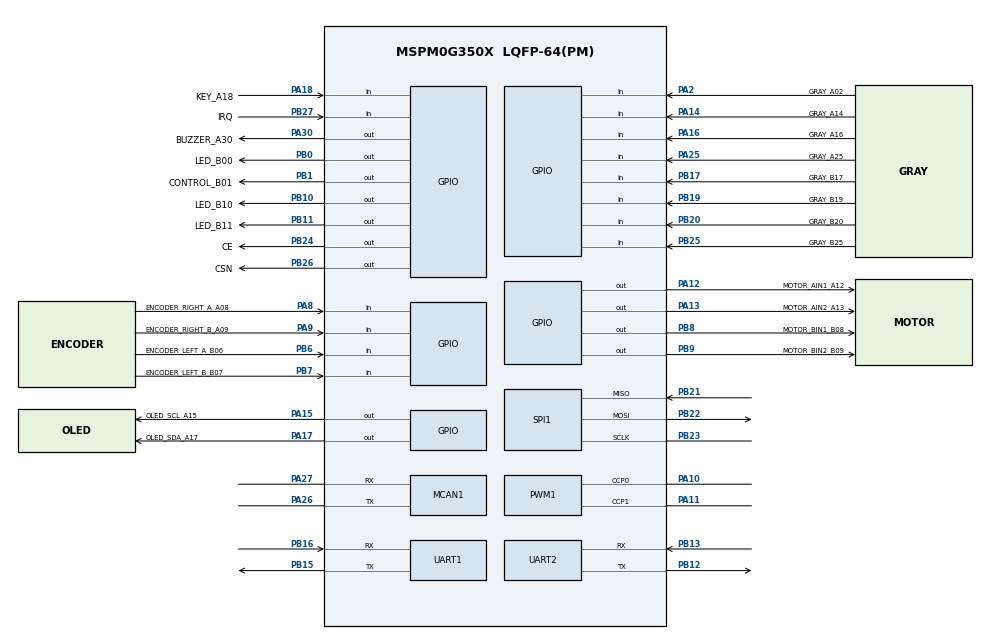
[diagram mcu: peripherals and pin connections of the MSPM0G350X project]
/**
 *
 * @cliArgs --device "MSPM0G350X" --part "Default" --package "LQFP-64(PM)" --product "mspm0_sdk@2.11.00.07"
 * @versions {"tool":"1.28.0+4696"}
 */

/**
 * Import the modules used in this configuration.
 */
const GPIO   = scripting.addModule("/ti/driverlib/GPIO", {}, false);
const GPIO1  = GPIO.addInstance();
const GPIO2  = GPIO.addInstance();
const GPIO3  = GPIO.addInstance();
const GPIO4  = GPIO.addInstance();
const GPIO5  = GPIO.addInstance();
const GPIO6  = GPIO.addInstance();
const GPIO7  = GPIO.addInstance();
const GPIO8  = GPIO.addInstance();
const GPIO9  = GPIO.addInstance();
const MCAN   = scripting.addModule("/ti/driverlib/MCAN", {}, false);
const MCAN1  = MCAN.addInstance();
const PWM    = scripting.addModule("/ti/driverlib/PWM", {}, false);
const PWM1   = PWM.addInstance();
const SPI    = scripting.addModule("/ti/driverlib/SPI", {}, false);
const SPI1   = SPI.addInstance();
const SYSCTL = scripting.addModule("/ti/driverlib/SYSCTL");
const UART   = scripting.addModule("/ti/driverlib/UART", {}, false);
const UART1  = UART.addInstance();
const UART2  = UART.addInstance();

/**
 * Write custom configuration values to the imported modules.
 */
GPIO1.$name                         = "GPIO_LEDS";
GPIO1.associatedPins.create(3);
GPIO1.associatedPins[0].$name       = "LED_B00";
GPIO1.associatedPins[0].pin.$assign = "PB0";
GPIO1.associatedPins[1].$name       = "LED_B10";
GPIO1.associatedPins[1].pin.$assign = "PB10";
GPIO1.associatedPins[2].$name       = "LED_B11";
GPIO1.associatedPins[2].pin.$assign = "PB11";

const Board = scripting.addModule("/ti/driverlib/Board", {}, false);

GPIO2.$name                         = "GPIO_GRAY";
GPIO2.associatedPins.create(8);
GPIO2.associatedPins[0].$name       = "GRAY_A02";
GPIO2.associatedPins[0].direction   = "INPUT";
GPIO2.associatedPins[0].pin.$assign = "PA2";
GPIO2.associatedPins[1].$name       = "GRAY_B19";
GPIO2.associatedPins[1].direction   = "INPUT";
GPIO2.associatedPins[1].pin.$assign = "PB19";
GPIO2.associatedPins[2].$name       = "GRAY_B17";
GPIO2.associatedPins[2].direction   = "INPUT";
GPIO2.associatedPins[2].pin.$assign = "PB17";
GPIO2.associatedPins[3].$name       = "GRAY_A16";
GPIO2.associatedPins[3].direction   = "INPUT";
GPIO2.associatedPins[3].pin.$assign = "PA16";
GPIO2.associatedPins[4].$name       = "GRAY_A14";
GPIO2.associatedPins[4].direction   = "INPUT";
GPIO2.associatedPins[4].pin.$assign = "PA14";
GPIO2.associatedPins[5].$name       = "GRAY_B20";
GPIO2.associatedPins[5].direction   = "INPUT";
GPIO2.associatedPins[5].pin.$assign = "PB20";
GPIO2.associatedPins[6].$name       = "GRAY_B25";
GPIO2.associatedPins[6].direction   = "INPUT";
GPIO2.associatedPins[6].pin.$assign = "PB25";
GPIO2.associatedPins[7].$name       = "GRAY_A25";
GPIO2.associatedPins[7].direction   = "INPUT";
GPIO2.associatedPins[7].pin.$assign = "PA25";

GPIO3.$name                                 = "GPIO_KEY";
GPIO3.associatedPins.create(2);
GPIO3.associatedPins[0].$name               = "KEY_A18";
GPIO3.associatedPins[0].direction           = "INPUT";
GPIO3.associatedPins[0].internalResistor    = "PULL_UP";
GPIO3.associatedPins[0].interruptEn         = true;
GPIO3.associatedPins[0].assignedPort        = "PORTA";
GPIO3.associatedPins[0].assignedPortSegment = "Upper";
GPIO3.associatedPins[0].assignedPin         = "18";
GPIO3.associatedPins[0].polarity            = "RISE_FALL";
GPIO3.associatedPins[0].pin.$assign         = "PA18";
GPIO3.associatedPins[1].$name               = "KEY_B14";
GPIO3.associatedPins[1].direction           = "INPUT";
GPIO3.associatedPins[1].internalResistor    = "PULL_UP";
GPIO3.associatedPins[1].assignedPin         = "14";
GPIO3.associatedPins[1].assignedPort        = "PORTB";
GPIO3.associatedPins[1].assignedPortSegment = "Lower";
GPIO3.associatedPins[1].interruptEn         = true;
GPIO3.associatedPins[1].polarity            = "RISE_FALL";

GPIO4.$name                              = "GPIO_OLED";
GPIO4.associatedPins.create(2);
GPIO4.associatedPins[0].$name            = "OLED_SCL_A15";
GPIO4.associatedPins[0].initialValue     = "SET";
GPIO4.associatedPins[0].internalResistor = "PULL_UP";
GPIO4.associatedPins[0].hiZ              = "ENABLE";
GPIO4.associatedPins[0].pin.$assign      = "PA15";
GPIO4.associatedPins[1].$name            = "OLED_SDA_A17";
GPIO4.associatedPins[1].initialValue     = "SET";
GPIO4.associatedPins[1].internalResistor = "PULL_UP";
GPIO4.associatedPins[1].hiZ              = "ENABLE";
GPIO4.associatedPins[1].pin.$assign      = "PA17";

GPIO5.$name                         = "GPIO_MOTOR_DIR";
GPIO5.associatedPins.create(4);
GPIO5.associatedPins[0].$name       = "MOTOR_AIN1_A12";
GPIO5.associatedPins[0].initialValue = "CLEARED";
GPIO5.associatedPins[0].pin.$assign = "PA12";
GPIO5.associatedPins[1].$name       = "MOTOR_AIN2_A13";
GPIO5.associatedPins[1].initialValue = "CLEARED";
GPIO5.associatedPins[1].pin.$assign = "PA13";
GPIO5.associatedPins[2].$name       = "MOTOR_BIN1_B08";
GPIO5.associatedPins[2].initialValue = "CLEARED";
GPIO5.associatedPins[2].pin.$assign = "PB8";
GPIO5.associatedPins[3].$name       = "MOTOR_BIN2_B09";
GPIO5.associatedPins[3].initialValue = "CLEARED";
GPIO5.associatedPins[3].pin.$assign = "PB9";

GPIO6.$name                                 = "GPIO_ENCODER";
GPIO6.associatedPins.create(4);
GPIO6.associatedPins[0].$name               = "ENCODER_LEFT_A_B06";
GPIO6.associatedPins[0].direction           = "INPUT";
GPIO6.associatedPins[0].internalResistor    = "PULL_UP";
GPIO6.associatedPins[0].interruptEn         = true;
GPIO6.associatedPins[0].assignedPort        = "PORTB";
GPIO6.associatedPins[0].assignedPortSegment = "Lower";
GPIO6.associatedPins[0].assignedPin         = "6";
GPIO6.associatedPins[0].polarity            = "RISE_FALL";
GPIO6.associatedPins[0].pin.$assign         = "PB6";
GPIO6.associatedPins[1].$name               = "ENCODER_LEFT_B_B07";
GPIO6.associatedPins[1].direction           = "INPUT";
GPIO6.associatedPins[1].internalResistor    = "PULL_UP";
GPIO6.associatedPins[1].interruptEn         = true;
GPIO6.associatedPins[1].assignedPort        = "PORTB";
GPIO6.associatedPins[1].assignedPortSegment = "Lower";
GPIO6.associatedPins[1].assignedPin         = "7";
GPIO6.associatedPins[1].polarity            = "RISE_FALL";
GPIO6.associatedPins[1].pin.$assign         = "PB7";
GPIO6.associatedPins[2].$name               = "ENCODER_RIGHT_A_A08";
GPIO6.associatedPins[2].direction           = "INPUT";
GPIO6.associatedPins[2].internalResistor    = "PULL_UP";
GPIO6.associatedPins[2].interruptEn         = true;
GPIO6.associatedPins[2].assignedPort        = "PORTA";
GPIO6.associatedPins[2].assignedPortSegment = "Lower";
GPIO6.associatedPins[2].assignedPin         = "8";
GPIO6.associatedPins[2].polarity            = "RISE_FALL";
GPIO6.associatedPins[2].pin.$assign         = "PA8";
GPIO6.associatedPins[3].$name               = "ENCODER_RIGHT_B_A09";
GPIO6.associatedPins[3].direction           = "INPUT";
GPIO6.associatedPins[3].internalResistor    = "PULL_UP";
GPIO6.associatedPins[3].interruptEn         = true;
GPIO6.associatedPins[3].assignedPort        = "PORTA";
GPIO6.associatedPins[3].assignedPortSegment = "Lower";
GPIO6.associatedPins[3].assignedPin         = "9";
GPIO6.associatedPins[3].polarity            = "RISE_FALL";
GPIO6.associatedPins[3].pin.$assign         = "PA9";

GPIO7.$name                              = "GPIO_BUZZER";
GPIO7.associatedPins[0].$name            = "BUZZER_A30";
GPIO7.associatedPins[0].initialValue     = "CLEARED";
GPIO7.associatedPins[0].pin.$assign      = "PA30";

GPIO8.$name                          = "GPIO_NRF24";
GPIO8.associatedPins.create(3);
GPIO8.associatedPins[0].$name        = "CE";
GPIO8.associatedPins[0].initialValue = "CLEARED";
GPIO8.associatedPins[0].pin.$assign  = "PB24";
GPIO8.associatedPins[1].$name        = "CSN";
GPIO8.associatedPins[1].initialValue = "SET";
GPIO8.associatedPins[1].pin.$assign  = "PB26";
GPIO8.associatedPins[2].$name        = "IRQ";
GPIO8.associatedPins[2].direction    = "INPUT";
GPIO8.associatedPins[2].internalResistor = "PULL_UP";
GPIO8.associatedPins[2].pin.$assign  = "PB27";

GPIO9.$name                          = "GPIO_ELECTROMAGNET";
GPIO9.associatedPins[0].$name        = "CONTROL_B01";
GPIO9.associatedPins[0].initialValue = "CLEARED";
GPIO9.associatedPins[0].pin.$assign  = "PB1";

SPI1.$name                      = "SPI_NRF24";
SPI1.targetBitRate              = 1000000;
SPI1.chipSelect                 = [];
SPI1.frameFormat                = "MOTO3";
SPI1.peripheral.$assign         = "SPI1";
SPI1.peripheral.sclkPin.$assign = "PB23";
SPI1.peripheral.mosiPin.$assign = "PB22";
SPI1.peripheral.misoPin.$assign = "PB21";

MCAN1.$name                    = "MCAN_GIMBAL";
MCAN1.additionalCoreConfig     = true;
MCAN1.rrfe                     = true;
MCAN1.rrfs                     = true;
MCAN1.anfe                     = "2";
MCAN1.anfs                     = "2";
MCAN1.lss                      = 0;
MCAN1.flesa                    = 0;
MCAN1.lse                      = 1;
MCAN1.extFiltElem              = "001";
MCAN1.extFiltType              = "00";
MCAN1.extFiltID1               = 0x100;
MCAN1.extFiltID2               = 0xFFFF;
MCAN1.txStartAddr              = 8;
MCAN1.txBufNum                 = 1;
MCAN1.txFIFOSize               = 0;
MCAN1.txBufElemSize            = "DL_MCAN_ELEM_SIZE_8BYTES";
MCAN1.txEventFIFOStartAddr     = 24;
MCAN1.txEventFIFOSize          = 0;
MCAN1.txEventFIFOWaterMark     = 0;
MCAN1.rxFIFO0startAddr         = 24;
MCAN1.rxFIFO0size              = 8;
MCAN1.rxFIFO0waterMark         = 1;
MCAN1.rxFIFO1startAddr         = 152;
MCAN1.rxFIFO1size              = 0;
MCAN1.rxFIFO1waterMark         = 0;
MCAN1.rxBufStartAddr           = 152;
MCAN1.rxFIFO0ElemSize          = "DL_MCAN_ELEM_SIZE_8BYTES";
MCAN1.rxFIFO1ElemSize          = "DL_MCAN_ELEM_SIZE_8BYTES";
MCAN1.rxBufElemSize            = "DL_MCAN_ELEM_SIZE_8BYTES";
MCAN1.desiredNomRate           = 500;
MCAN1.enableInterrupt          = true;
MCAN1.interruptFlags           = ["DL_MCAN_INTERRUPT_RF0N"];
MCAN1.interruptLine            = ["DL_MCAN_INTR_LINE_NUM_1"];
MCAN1.interruptLine1Flag       = ["DL_MCAN_INTR_MASK_ALL"];
MCAN1.m0interrupts             = ["DL_MCAN_MSP_INTERRUPT_LINE1"];
MCAN1.peripheral.$assign       = "CANFD0";
MCAN1.peripheral.txPin.$assign = "PA26";
MCAN1.peripheral.rxPin.$assign = "PA27";

PWM1.$name                      = "PWM_MOTOR";
PWM1.timerCount                 = 3999;
PWM1.timerStartTimer            = false;
PWM1.dutyArgs                   = "[0,0,0,0]";
PWM1.peripheral.$assign         = "TIMA1";
PWM1.peripheral.ccp0Pin.$assign = "PA10";
PWM1.peripheral.ccp1Pin.$assign = "PA11";
PWM1.PWM_CHANNEL_0.$name        = "PWM_MOTOR_LEFT";
PWM1.PWM_CHANNEL_1.$name        = "PWM_MOTOR_RIGHT";

UART1.$name                             = "UART_IMU0";
UART1.targetBaudRate                    = 460800;
UART1.enableFIFO                        = true;
UART1.rxFifoThreshold                   = "DL_UART_RX_FIFO_LEVEL_ONE_ENTRY";
UART1.rxTimeoutValue                    = 15;
UART1.enabledInterrupts                 = ["DMA_DONE_RX","RX_TIMEOUT_ERROR"];
UART1.enabledDMARXTriggers              = "DL_UART_DMA_INTERRUPT_RX";
UART1.enableDMATX                       = false;
UART1.peripheral.$assign                = "UART2";
UART1.peripheral.rxPin.$assign          = "PB16";
UART1.peripheral.txPin.$assign          = "PB15";
UART1.DMA_CHANNEL_RX.$name              = "DMA_CH_IMU0_RX";
UART1.DMA_CHANNEL_RX.addressMode        = "f2b";
UART1.DMA_CHANNEL_RX.srcLength          = "BYTE";
UART1.DMA_CHANNEL_RX.dstLength          = "BYTE";
UART1.DMA_CHANNEL_RX.peripheral.$assign = "DMA_CH0";

UART2.$name                    = "UART_HC12";
UART2.targetBaudRate           = 9600;
UART2.enableFIFO               = true;
UART2.rxFifoThreshold          = "DL_UART_RX_FIFO_LEVEL_ONE_ENTRY";
UART2.enabledInterrupts        = ["RX"];
UART2.peripheral.$assign       = "UART3";
UART2.peripheral.rxPin.$assign = "PB13";
UART2.peripheral.txPin.$assign = "PB12";

SYSCTL.SYSPLL_CLK2XEn    = true;
SYSCTL.SYSPLL_CLK1En     = true;
SYSCTL.SYSPLL_Pdiv       = 1;
SYSCTL.SYSPLL_Qdiv       = 5;
SYSCTL.SYSPLL_CLK2XDiv   = 3;
SYSCTL.MCLKSource        = "HSCLK";
SYSCTL.HSCLKSource       = "SYSPLLCLK2X";
SYSCTL.CANCLKSource      = "SYSPLLCLK1";
SYSCTL.validateClkStatus = true;

/**
 * Pinmux solution for unlocked pins/peripherals. This ensures that minor changes to the automatic solver in a future
 * version of the tool will not impact the pinmux you originally saw.  These lines can be completely deleted in order to
 * re-solve from scratch.
 */
Board.peripheral.$suggestSolution            = "DEBUGSS";
Board.peripheral.swclkPin.$suggestSolution   = "PA20";
Board.peripheral.swdioPin.$suggestSolution   = "PA19";
GPIO3.associatedPins[1].pin.$suggestSolution = "PB14";
SYSCTL.peripheral.$suggestSolution           = "SYSCTL";
